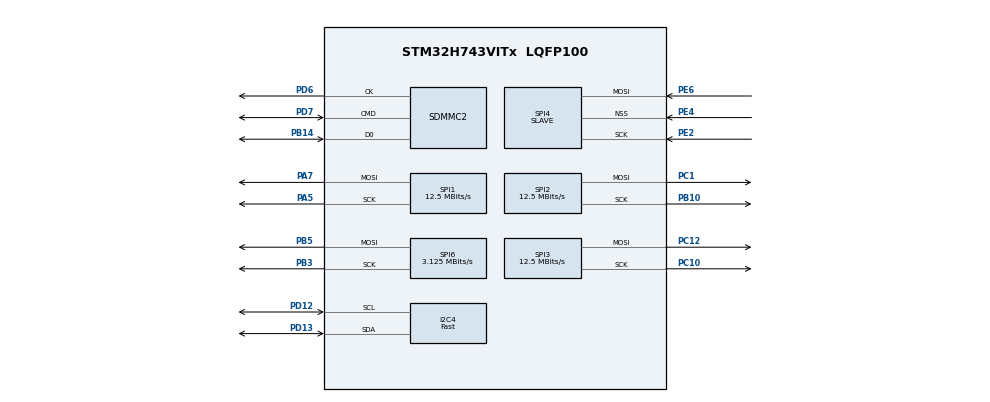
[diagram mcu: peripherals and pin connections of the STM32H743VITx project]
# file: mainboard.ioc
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Bdma.Request0=SPI6_TX
Bdma.RequestsNb=1
Bdma.SPI6_TX.0.Direction=DMA_MEMORY_TO_PERIPH
Bdma.SPI6_TX.0.EventEnable=DISABLE
Bdma.SPI6_TX.0.Instance=BDMA_Channel0
Bdma.SPI6_TX.0.MemDataAlignment=DMA_MDATAALIGN_BYTE
Bdma.SPI6_TX.0.MemInc=DMA_MINC_ENABLE
Bdma.SPI6_TX.0.Mode=DMA_NORMAL
Bdma.SPI6_TX.0.PeriphDataAlignment=DMA_PDATAALIGN_BYTE
Bdma.SPI6_TX.0.PeriphInc=DMA_PINC_DISABLE
Bdma.SPI6_TX.0.Polarity=HAL_DMAMUX_REQ_GEN_RISING
Bdma.SPI6_TX.0.Priority=DMA_PRIORITY_LOW
Bdma.SPI6_TX.0.RequestNumber=1
Bdma.SPI6_TX.0.SignalID=HAL_DMAMUX2_REQ_GEN_I2C4_WKUP
Bdma.SPI6_TX.0.SyncEnable=DISABLE
Bdma.SPI6_TX.0.SyncPolarity=HAL_DMAMUX_SYNC_NO_EVENT
Bdma.SPI6_TX.0.SyncRequestNumber=1
Bdma.SPI6_TX.0.SyncSignalID=HAL_DMAMUX2_SYNC_I2C4_WKUP
Dma.Request0=SPI1_TX
Dma.Request1=SPI2_TX
Dma.Request2=SPI3_TX
Dma.SPI1_TX.0.Direction=DMA_MEMORY_TO_PERIPH
Dma.SPI1_TX.0.EventEnable=DISABLE
Dma.SPI1_TX.0.FIFOMode=DMA_FIFOMODE_DISABLE
Dma.SPI1_TX.0.Instance=DMA1_Stream0
Dma.SPI1_TX.0.MemDataAlignment=DMA_MDATAALIGN_BYTE
Dma.SPI1_TX.0.MemInc=DMA_MINC_ENABLE
Dma.SPI1_TX.0.Mode=DMA_NORMAL
Dma.SPI1_TX.0.PeriphDataAlignment=DMA_PDATAALIGN_BYTE
Dma.SPI1_TX.0.PeriphInc=DMA_PINC_DISABLE
Dma.SPI1_TX.0.Polarity=HAL_DMAMUX_REQ_GEN_RISING
Dma.SPI1_TX.0.Priority=DMA_PRIORITY_LOW
Dma.SPI1_TX.0.RequestNumber=1
Dma.SPI1_TX.0.SyncEnable=DISABLE
Dma.SPI1_TX.0.SyncPolarity=HAL_DMAMUX_SYNC_NO_EVENT
Dma.SPI1_TX.0.SyncRequestNumber=1
Dma.SPI2_TX.1.Direction=DMA_MEMORY_TO_PERIPH
Dma.SPI2_TX.1.EventEnable=DISABLE
Dma.SPI2_TX.1.FIFOMode=DMA_FIFOMODE_DISABLE
Dma.SPI2_TX.1.Instance=DMA1_Stream1
Dma.SPI2_TX.1.MemDataAlignment=DMA_MDATAALIGN_BYTE
Dma.SPI2_TX.1.MemInc=DMA_MINC_ENABLE
Dma.SPI2_TX.1.Mode=DMA_NORMAL
Dma.SPI2_TX.1.PeriphDataAlignment=DMA_PDATAALIGN_BYTE
Dma.SPI2_TX.1.PeriphInc=DMA_PINC_DISABLE
Dma.SPI2_TX.1.Polarity=HAL_DMAMUX_REQ_GEN_RISING
Dma.SPI2_TX.1.Priority=DMA_PRIORITY_LOW
Dma.SPI2_TX.1.RequestNumber=1
Dma.SPI2_TX.1.SyncEnable=DISABLE
Dma.SPI2_TX.1.SyncPolarity=HAL_DMAMUX_SYNC_NO_EVENT
Dma.SPI2_TX.1.SyncRequestNumber=1
Dma.SPI3_TX.2.Direction=DMA_MEMORY_TO_PERIPH
Dma.SPI3_TX.2.EventEnable=DISABLE
Dma.SPI3_TX.2.FIFOMode=DMA_FIFOMODE_DISABLE
Dma.SPI3_TX.2.Instance=DMA2_Stream0
Dma.SPI3_TX.2.MemDataAlignment=DMA_MDATAALIGN_BYTE
Dma.SPI3_TX.2.MemInc=DMA_MINC_ENABLE
Dma.SPI3_TX.2.Mode=DMA_NORMAL
Dma.SPI3_TX.2.PeriphDataAlignment=DMA_PDATAALIGN_BYTE
Dma.SPI3_TX.2.PeriphInc=DMA_PINC_DISABLE
Dma.SPI3_TX.2.Polarity=HAL_DMAMUX_REQ_GEN_RISING
Dma.SPI3_TX.2.Priority=DMA_PRIORITY_LOW
Dma.SPI3_TX.2.RequestNumber=1
Dma.SPI3_TX.2.SyncEnable=DISABLE
Dma.SPI3_TX.2.SyncPolarity=HAL_DMAMUX_SYNC_NO_EVENT
Dma.SPI3_TX.2.SyncRequestNumber=1
FREERTOS.Tasks01=defaultTask,0,128,StartDefaultTask,Default,NULL
I2C4.I2C_Speed_Mode=I2C_Fast
I2C4.Timing=0x009034B6
Mcu.Family=STM32H7
Mcu.Name=STM32H743VITx
Mcu.Package=LQFP100
NVIC.BDMA_Channel0_IRQn=true\:5\:0\:false\:false\:true\:true\:false
NVIC.DMA1_Stream0_IRQn=true\:5\:0\:false\:false\:true\:true\:false
NVIC.DMA1_Stream1_IRQn=true\:5\:0\:false\:false\:true\:true\:false
NVIC.DMA2_Stream0_IRQn=true\:5\:0\:false\:false\:true\:true\:false
NVIC.PriorityGroup=NVIC_PRIORITYGROUP_4
NVIC.SPI1_IRQn=true\:5\:0\:false\:false\:true\:true\:false
NVIC.SPI2_IRQn=true\:5\:0\:false\:false\:true\:true\:false
NVIC.SPI3_IRQn=true\:5\:0\:false\:false\:true\:true\:false
NVIC.SPI4_IRQn=true\:5\:0\:false\:false\:true\:true\:true
NVIC.SPI6_IRQn=true\:5\:0\:false\:false\:true\:true\:false
NVIC.TIM1_UP_IRQn=true\:0\:0\:false\:false\:true\:false\:false
NVIC.TimeBase=TIM1_UP_IRQn
NVIC.TimeBaseIP=TIM1
PA5.GPIO_Speed=GPIO_SPEED_FREQ_VERY_HIGH
PA5.Mode=TX_Only_Simplex_Unidirect_Master
PA5.Signal=SPI1_SCK
PA7.GPIO_Speed=GPIO_SPEED_FREQ_VERY_HIGH
PA7.Mode=TX_Only_Simplex_Unidirect_Master
PA7.Signal=SPI1_MOSI
PB10.GPIO_Speed=GPIO_SPEED_FREQ_VERY_HIGH
PB10.Mode=TX_Only_Simplex_Unidirect_Master
PB10.Signal=SPI2_SCK
PB14.Mode=SD_1_bit
PB14.Signal=SDMMC2_D0
PB3\ (JTDO/TRACESWO).GPIO_Speed=GPIO_SPEED_FREQ_VERY_HIGH
PB3\ (JTDO/TRACESWO).Mode=TX_Only_Simplex_Unidirect_Master
PB3\ (JTDO/TRACESWO).Signal=SPI6_SCK
PB5.GPIO_Speed=GPIO_SPEED_FREQ_VERY_HIGH
PB5.Mode=TX_Only_Simplex_Unidirect_Master
PB5.Signal=SPI6_MOSI
PC1.Mode=TX_Only_Simplex_Unidirect_Master
PC1.Signal=SPI2_MOSI
PC10.GPIO_Speed=GPIO_SPEED_FREQ_VERY_HIGH
PC10.Mode=TX_Only_Simplex_Unidirect_Master
PC10.Signal=SPI3_SCK
PC12.GPIO_Speed=GPIO_SPEED_FREQ_VERY_HIGH
PC12.Mode=TX_Only_Simplex_Unidirect_Master
PC12.Signal=SPI3_MOSI
PD12.Mode=I2C
PD12.Signal=I2C4_SCL
PD13.Mode=I2C
PD13.Signal=I2C4_SDA
PD6.Mode=SD_1_bit
PD6.Signal=SDMMC2_CK
PD7.Mode=SD_1_bit
PD7.Signal=SDMMC2_CMD
PE2.GPIO_Speed=GPIO_SPEED_FREQ_VERY_HIGH
PE2.Mode=RX_Only_Simplex_Unidirect_Slave
PE2.Signal=SPI4_SCK
PE4.Mode=NSS_Signal_Hard_Input
PE4.Signal=SPI4_NSS
PE6.Mode=RX_Only_Simplex_Unidirect_Slave
PE6.Signal=SPI4_MOSI
ProjectManager.HeapSize=0x200
ProjectManager.StackSize=0x400
ProjectManager.TargetToolchain=Makefile
RCC.ADCFreq_Value=129000000
RCC.APB1Freq_Value=100000000
RCC.APB2Freq_Value=100000000
RCC.APB3Freq_Value=100000000
RCC.APB4Freq_Value=100000000
RCC.CortexFreq_Value=400000000
RCC.DIVM1=16
RCC.DIVN1=200
RCC.HCLKFreq_Value=100000000
RCC.HPRE=RCC_HCLK_DIV4
RCC.SYSCLKFreq_VALUE=400000000
RCC.SYSCLKSource=RCC_SYSCLKSOURCE_PLLCLK
RCC.USBFreq_Value=400000000
SPI1.BaudRatePrescaler=SPI_BAUDRATEPRESCALER_32
SPI1.CalculateBaudRate=12.5 MBits/s
SPI1.DataSize=SPI_DATASIZE_8BIT
SPI1.Direction=SPI_DIRECTION_2LINES_TXONLY
SPI1.Mode=SPI_MODE_MASTER
SPI1.VirtualType=VM_MASTER
SPI2.BaudRatePrescaler=SPI_BAUDRATEPRESCALER_32
SPI2.CalculateBaudRate=12.5 MBits/s
SPI2.DataSize=SPI_DATASIZE_8BIT
SPI2.Direction=SPI_DIRECTION_2LINES_TXONLY
SPI2.Mode=SPI_MODE_MASTER
SPI2.VirtualType=VM_MASTER
SPI3.BaudRatePrescaler=SPI_BAUDRATEPRESCALER_32
SPI3.CalculateBaudRate=12.5 MBits/s
SPI3.DataSize=SPI_DATASIZE_8BIT
SPI3.Direction=SPI_DIRECTION_2LINES_TXONLY
SPI3.Mode=SPI_MODE_MASTER
SPI3.VirtualType=VM_MASTER
SPI4.DataSize=SPI_DATASIZE_8BIT
SPI4.Direction=SPI_DIRECTION_2LINES_RXONLY
SPI4.Mode=SPI_MODE_SLAVE
SPI4.VirtualNSS=VM_NSSHARD
SPI4.VirtualType=VM_SLAVE
SPI6.BaudRatePrescaler=SPI_BAUDRATEPRESCALER_32
SPI6.CalculateBaudRate=3.125 MBits/s
SPI6.DataSize=SPI_DATASIZE_8BIT
SPI6.Direction=SPI_DIRECTION_2LINES_TXONLY
SPI6.Mode=SPI_MODE_MASTER
SPI6.VirtualType=VM_MASTER
VP_FATFS_VS_Generic.Mode=User_defined
VP_FATFS_VS_SDIO.Mode=SDIO
VP_FREERTOS_VS_ENABLE.Mode=Enabled
VP_SYS_VS_tim1.Mode=TIM1
board=custom

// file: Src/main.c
/* USER CODE BEGIN Header */
/**
  ******************************************************************************
  * @file           : main.c
  * @brief          : Main program body
  ******************************************************************************
  * This notice applies to any and all portions of this file
  * that are not between comment pairs USER CODE BEGIN and
  * USER CODE END. Other portions of this file, whether
  * inserted by the user or by software development tools
  * are owned by their respective copyright owners.
  *
  * Copyright (c) 2019 STMicroelectronics International N.V.
  * All rights reserved.
  *
  * Redistribution and use in source and binary forms, with or without
  * modification, are permitted, provided that the following conditions are met:
  *
  * 1. Redistribution of source code must retain the above copyright notice,
  *    this list of conditions and the following disclaimer.
  * 2. Redistributions in binary form must reproduce the above copyright notice,
  *    this list of conditions and the following disclaimer in the documentation
  *    and/or other materials provided with the distribution.
  * 3. Neither the name of STMicroelectronics nor the names of other
  *    contributors to this software may be used to endorse or promote products
  *    derived from this software without specific written permission.
  * 4. This software, including modifications and/or derivative works of this
  *    software, must execute solely and exclusively on microcontroller or
  *    microprocessor devices manufactured by or for STMicroelectronics.
  * 5. Redistribution and use of this software other than as permitted under
  *    this license is void and will automatically terminate your rights under
  *    this license.
  *
  * THIS SOFTWARE IS PROVIDED BY STMICROELECTRONICS AND CONTRIBUTORS "AS IS"
  * AND ANY EXPRESS, IMPLIED OR STATUTORY WARRANTIES, INCLUDING, BUT NOT
  * LIMITED TO, THE IMPLIED WARRANTIES OF MERCHANTABILITY, FITNESS FOR A
  * PARTICULAR PURPOSE AND NON-INFRINGEMENT OF THIRD PARTY INTELLECTUAL PROPERTY
  * RIGHTS ARE DISCLAIMED TO THE FULLEST EXTENT PERMITTED BY LAW. IN NO EVENT
  * SHALL STMICROELECTRONICS OR CONTRIBUTORS BE LIABLE FOR ANY DIRECT, INDIRECT,
  * INCIDENTAL, SPECIAL, EXEMPLARY, OR CONSEQUENTIAL DAMAGES (INCLUDING, BUT NOT
  * LIMITED TO, PROCUREMENT OF SUBSTITUTE GOODS OR SERVICES; LOSS OF USE, DATA,
  * OR PROFITS; OR BUSINESS INTERRUPTION) HOWEVER CAUSED AND ON ANY THEORY OF
  * LIABILITY, WHETHER IN CONTRACT, STRICT LIABILITY, OR TORT (INCLUDING
  * NEGLIGENCE OR OTHERWISE) ARISING IN ANY WAY OUT OF THE USE OF THIS SOFTWARE,
  * EVEN IF ADVISED OF THE POSSIBILITY OF SUCH DAMAGE.
  *
  ******************************************************************************
  */
/* USER CODE END Header */

#include "main.h"
#include "cmsis_os.h"
#include "bdma.h"
#include "dma.h"
#include "fatfs.h"
#include "i2c.h"
#include "sdmmc.h"
#include "spi.h"
#include "gpio.h"

/* USER CODE BEGIN Includes */
#include "main_task.h"
#include "SEGGER_RTT.h"

/* USER CODE END Includes */

/* USER CODE BEGIN PV */
osThreadId main_task_handle;

/* USER CODE END PV */

void SystemClock_Config(void);
void MX_FREERTOS_Init(void);

int main(void)
{

  /* MCU Configuration--------------------------------------------------------*/

  /* Reset of all peripherals, Initializes the Flash interface and the Systick. */
  HAL_Init();

  /* Configure the system clock */
  SystemClock_Config();

  /* Initialize all configured peripherals */
  MX_GPIO_Init();
  MX_BDMA_Init();
  MX_DMA_Init();
  MX_SDMMC2_SD_Init();
  MX_I2C4_Init();
  MX_SPI1_Init();
  MX_SPI2_Init();
  MX_SPI3_Init();
  MX_SPI6_Init();
  MX_SPI4_Init();
  /* USER CODE BEGIN 2 */
  SEGGER_RTT_printf(0,"error hal state i2c %x\r\n",HAL_I2C_GetState(&hi2c4));
	struct main_task_args args = {
		.spi_strip_dev_1 = &hspi1,
		.spi_esp_dev = &hspi4,
		.i2c_dev = &hi2c4
	};
  osThreadDef(main_thread, main_task, osPriorityNormal, 0, 1024);
  main_task_handle = osThreadCreate(osThread(main_thread), &args);

  /* USER CODE END 2 */

  /* Call init function for freertos objects (in freertos.c) */
  MX_FREERTOS_Init();

  /* Start scheduler */
  osKernelStart();

  /* We should never get here as control is now taken by the scheduler */

  /* Infinite loop */
  while (1)
  {

  }
}

void SystemClock_Config(void)
{
  RCC_OscInitTypeDef RCC_OscInitStruct = {0};
  RCC_ClkInitTypeDef RCC_ClkInitStruct = {0};
  RCC_PeriphCLKInitTypeDef PeriphClkInitStruct = {0};

  /**Supply configuration update enable
  */
  MODIFY_REG(PWR->CR3, PWR_CR3_SCUEN, 0);
  /**Configure the main internal regulator output voltage
  */
  __HAL_PWR_VOLTAGESCALING_CONFIG(PWR_REGULATOR_VOLTAGE_SCALE1);

  while ((PWR->D3CR & (PWR_D3CR_VOSRDY)) != PWR_D3CR_VOSRDY)
  {

  }
  /**Initializes the CPU, AHB and APB busses clocks
  */
  RCC_OscInitStruct.OscillatorType = RCC_OSCILLATORTYPE_HSI;
  RCC_OscInitStruct.HSIState = RCC_HSI_DIV1;
  RCC_OscInitStruct.HSICalibrationValue = RCC_HSICALIBRATION_DEFAULT;
  RCC_OscInitStruct.PLL.PLLState = RCC_PLL_ON;
  RCC_OscInitStruct.PLL.PLLSource = RCC_PLLSOURCE_HSI;
  RCC_OscInitStruct.PLL.PLLM = 16;
  RCC_OscInitStruct.PLL.PLLN = 200;
  RCC_OscInitStruct.PLL.PLLP = 2;
  RCC_OscInitStruct.PLL.PLLQ = 2;
  RCC_OscInitStruct.PLL.PLLR = 2;
  RCC_OscInitStruct.PLL.PLLRGE = RCC_PLL1VCIRANGE_2;
  RCC_OscInitStruct.PLL.PLLVCOSEL = RCC_PLL1VCOWIDE;
  RCC_OscInitStruct.PLL.PLLFRACN = 0;
  if (HAL_RCC_OscConfig(&RCC_OscInitStruct) != HAL_OK)
  {
    Error_Handler();
  }
  /**Initializes the CPU, AHB and APB busses clocks
  */
  RCC_ClkInitStruct.ClockType = RCC_CLOCKTYPE_HCLK|RCC_CLOCKTYPE_SYSCLK
                              |RCC_CLOCKTYPE_PCLK1|RCC_CLOCKTYPE_PCLK2
                              |RCC_CLOCKTYPE_D3PCLK1|RCC_CLOCKTYPE_D1PCLK1;
  RCC_ClkInitStruct.SYSCLKSource = RCC_SYSCLKSOURCE_PLLCLK;
  RCC_ClkInitStruct.SYSCLKDivider = RCC_SYSCLK_DIV1;
  RCC_ClkInitStruct.AHBCLKDivider = RCC_HCLK_DIV4;
  RCC_ClkInitStruct.APB3CLKDivider = RCC_APB3_DIV1;
  RCC_ClkInitStruct.APB1CLKDivider = RCC_APB1_DIV1;
  RCC_ClkInitStruct.APB2CLKDivider = RCC_APB2_DIV1;
  RCC_ClkInitStruct.APB4CLKDivider = RCC_APB4_DIV1;

  if (HAL_RCC_ClockConfig(&RCC_ClkInitStruct, FLASH_LATENCY_1) != HAL_OK)
  {
    Error_Handler();
  }
  PeriphClkInitStruct.PeriphClockSelection = RCC_PERIPHCLK_SPI4|RCC_PERIPHCLK_SPI3
                              |RCC_PERIPHCLK_SPI1|RCC_PERIPHCLK_SPI2
                              |RCC_PERIPHCLK_SDMMC|RCC_PERIPHCLK_SPI6
                              |RCC_PERIPHCLK_I2C4;
  PeriphClkInitStruct.SdmmcClockSelection = RCC_SDMMCCLKSOURCE_PLL;
  PeriphClkInitStruct.Spi123ClockSelection = RCC_SPI123CLKSOURCE_PLL;
  PeriphClkInitStruct.Spi45ClockSelection = RCC_SPI45CLKSOURCE_D2PCLK1;
  PeriphClkInitStruct.I2c4ClockSelection = RCC_I2C4CLKSOURCE_D3PCLK1;
  PeriphClkInitStruct.Spi6ClockSelection = RCC_SPI6CLKSOURCE_D3PCLK1;
  if (HAL_RCCEx_PeriphCLKConfig(&PeriphClkInitStruct) != HAL_OK)
  {
    Error_Handler();
  }
}

void HAL_TIM_PeriodElapsedCallback(TIM_HandleTypeDef *htim)
{
  if (htim->Instance == TIM1) {
    HAL_IncTick();
  }
}

void Error_Handler(void)
{
}

/************************ (C) COPYRIGHT STMicroelectronics *****END OF FILE****/

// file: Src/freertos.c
/* USER CODE BEGIN Header */
/**
  ******************************************************************************
  * File Name          : freertos.c
  * Description        : Code for freertos applications
  ******************************************************************************
  * This notice applies to any and all portions of this file
  * that are not between comment pairs USER CODE BEGIN and
  * USER CODE END. Other portions of this file, whether
  * inserted by the user or by software development tools
  * are owned by their respective copyright owners.
  *
  * Copyright (c) 2019 STMicroelectronics International N.V.
  * All rights reserved.
  *
  * Redistribution and use in source and binary forms, with or without
  * modification, are permitted, provided that the following conditions are met:
  *
  * 1. Redistribution of source code must retain the above copyright notice,
  *    this list of conditions and the following disclaimer.
  * 2. Redistributions in binary form must reproduce the above copyright notice,
  *    this list of conditions and the following disclaimer in the documentation
  *    and/or other materials provided with the distribution.
  * 3. Neither the name of STMicroelectronics nor the names of other
  *    contributors to this software may be used to endorse or promote products
  *    derived from this software without specific written permission.
  * 4. This software, including modifications and/or derivative works of this
  *    software, must execute solely and exclusively on microcontroller or
  *    microprocessor devices manufactured by or for STMicroelectronics.
  * 5. Redistribution and use of this software other than as permitted under
  *    this license is void and will automatically terminate your rights under
  *    this license.
  *
  * THIS SOFTWARE IS PROVIDED BY STMICROELECTRONICS AND CONTRIBUTORS "AS IS"
  * AND ANY EXPRESS, IMPLIED OR STATUTORY WARRANTIES, INCLUDING, BUT NOT
  * LIMITED TO, THE IMPLIED WARRANTIES OF MERCHANTABILITY, FITNESS FOR A
  * PARTICULAR PURPOSE AND NON-INFRINGEMENT OF THIRD PARTY INTELLECTUAL PROPERTY
  * RIGHTS ARE DISCLAIMED TO THE FULLEST EXTENT PERMITTED BY LAW. IN NO EVENT
  * SHALL STMICROELECTRONICS OR CONTRIBUTORS BE LIABLE FOR ANY DIRECT, INDIRECT,
  * INCIDENTAL, SPECIAL, EXEMPLARY, OR CONSEQUENTIAL DAMAGES (INCLUDING, BUT NOT
  * LIMITED TO, PROCUREMENT OF SUBSTITUTE GOODS OR SERVICES; LOSS OF USE, DATA,
  * OR PROFITS; OR BUSINESS INTERRUPTION) HOWEVER CAUSED AND ON ANY THEORY OF
  * LIABILITY, WHETHER IN CONTRACT, STRICT LIABILITY, OR TORT (INCLUDING
  * NEGLIGENCE OR OTHERWISE) ARISING IN ANY WAY OUT OF THE USE OF THIS SOFTWARE,
  * EVEN IF ADVISED OF THE POSSIBILITY OF SUCH DAMAGE.
  *
  ******************************************************************************
  */
/* USER CODE END Header */

#include "FreeRTOS.h"
#include "task.h"
#include "main.h"
#include "cmsis_os.h"

osThreadId defaultTaskHandle;

void StartDefaultTask(void const * argument);

extern void MX_FATFS_Init(void);
void MX_FREERTOS_Init(void); /* (MISRA C 2004 rule 8.1) */

void MX_FREERTOS_Init(void) {

  /* Create the thread(s) */
  /* definition and creation of defaultTask */
  osThreadDef(defaultTask, StartDefaultTask, osPriorityNormal, 0, 128);
  defaultTaskHandle = osThreadCreate(osThread(defaultTask), NULL);

}

void StartDefaultTask(void const * argument)
{
  /* init code for FATFS */
  MX_FATFS_Init();

  for(;;)
  {
    osDelay(1);
  }
}

/************************ (C) COPYRIGHT STMicroelectronics *****END OF FILE****/
